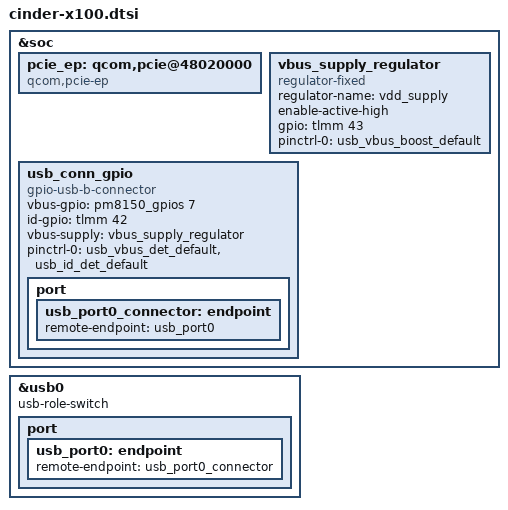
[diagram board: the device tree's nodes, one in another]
#include "cinder-pmic-overlay.dtsi"
#include <dt-bindings/gpio/gpio.h>

&soc {
	pcie_ep: qcom,pcie@48020000 {
		compatible = "qcom,pcie-ep";
		status = "ok";
	};

	vbus_supply_regulator: vbus_supply_regulator {
		compatible = "regulator-fixed";
		regulator-name = "vdd_supply";
		enable-active-high;
		gpio = <&tlmm 43 GPIO_ACTIVE_HIGH>;
		pinctrl-names = "default";
		pinctrl-0 = <&usb_vbus_boost_default>;
	};

	usb_conn_gpio: usb_conn_gpio {
		compatible = "gpio-usb-b-connector";
		vbus-gpio =  <&pm8150_gpios 7 GPIO_ACTIVE_HIGH>;
		id-gpio = <&tlmm 42 GPIO_ACTIVE_HIGH>;
		vbus-supply = <&vbus_supply_regulator>;

		pinctrl-names = "default";
		pinctrl-0 = <&usb_vbus_det_default
			     &usb_id_det_default>;

		port {
			usb_port0_connector: endpoint {
				remote-endpoint = <&usb_port0>;
			};
		};
	};
};

&usb0 {
	usb-role-switch;
	port {
		usb_port0: endpoint {
			remote-endpoint = <&usb_port0_connector>;
		};
	};
};
